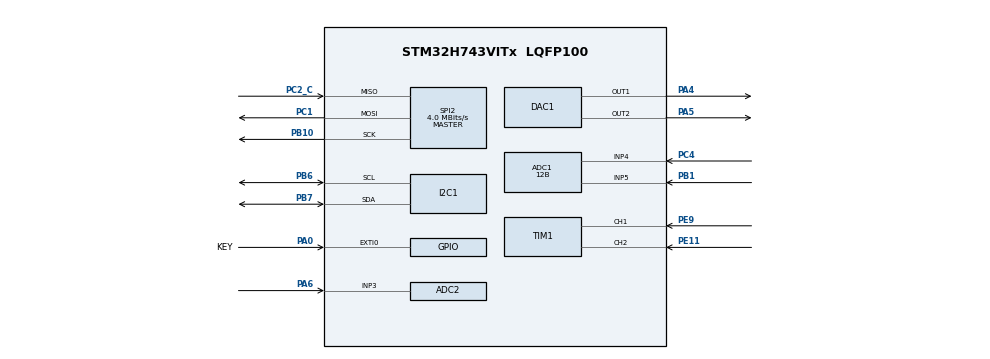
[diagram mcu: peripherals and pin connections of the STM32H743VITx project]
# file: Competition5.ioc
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ADC1.Channel-0\#ChannelRegularConversion=ADC_CHANNEL_5
ADC1.Channel-1\#ChannelRegularConversion=ADC_CHANNEL_4
ADC1.ConversionDataManagement=ADC_CONVERSIONDATA_DMA_CIRCULAR
ADC1.DiscontinuousConvMode=DISABLE
ADC1.ExternalTrigConv=ADC_EXTERNALTRIG_T2_TRGO
ADC1.Mode=ADC_MODE_INDEPENDENT
ADC1.NbrOfConversion=2
ADC1.NbrOfConversionFlag=1
ADC1.OffsetNumber-0\#ChannelRegularConversion=ADC_OFFSET_NONE
ADC1.OffsetNumber-1\#ChannelRegularConversion=ADC_OFFSET_NONE
ADC1.OffsetSignedSaturation-0\#ChannelRegularConversion=DISABLE
ADC1.Rank-0\#ChannelRegularConversion=1
ADC1.Rank-1\#ChannelRegularConversion=2
ADC1.Resolution=ADC_RESOLUTION_12B
ADC1.SamplingTime-0\#ChannelRegularConversion=ADC_SAMPLETIME_16CYCLES_5
ADC1.SamplingTime-1\#ChannelRegularConversion=ADC_SAMPLETIME_16CYCLES_5
ADC1.master=1
ADC2.Channel-3\#ChannelRegularConversion=ADC_CHANNEL_3
ADC2.ConversionDataManagement=ADC_CONVERSIONDATA_DMA_CIRCULAR
ADC2.ExternalTrigConv=ADC_EXTERNALTRIG_T3_TRGO
ADC2.NbrOfConversionFlag=1
ADC2.OffsetNumber-3\#ChannelRegularConversion=ADC_OFFSET_NONE
ADC2.OffsetSignedSaturation-3\#ChannelRegularConversion=DISABLE
ADC2.Rank-3\#ChannelRegularConversion=1
ADC2.Resolution=ADC_RESOLUTION_12B
ADC2.SamplingTime-3\#ChannelRegularConversion=ADC_SAMPLETIME_1CYCLE_5
CORTEX_M7.default_mode_Activation=1
DAC1.DAC_Channel-DAC_OUT1=DAC_CHANNEL_1
DAC1.DAC_Channel-DAC_OUT2=DAC_CHANNEL_2
DAC1.DAC_Trigger-DAC_OUT1=DAC_TRIGGER_T4_TRGO
DAC1.DAC_Trigger-DAC_OUT2=DAC_TRIGGER_T4_TRGO
Dma.ADC1.0.Direction=DMA_PERIPH_TO_MEMORY
Dma.ADC1.0.EventEnable=DISABLE
Dma.ADC1.0.FIFOMode=DMA_FIFOMODE_DISABLE
Dma.ADC1.0.Instance=DMA1_Stream0
Dma.ADC1.0.MemDataAlignment=DMA_MDATAALIGN_HALFWORD
Dma.ADC1.0.MemInc=DMA_MINC_ENABLE
Dma.ADC1.0.Mode=DMA_CIRCULAR
Dma.ADC1.0.PeriphDataAlignment=DMA_PDATAALIGN_HALFWORD
Dma.ADC1.0.PeriphInc=DMA_PINC_DISABLE
Dma.ADC1.0.Polarity=HAL_DMAMUX_REQ_GEN_RISING
Dma.ADC1.0.Priority=DMA_PRIORITY_LOW
Dma.ADC1.0.RequestNumber=1
Dma.ADC1.0.SignalID=NONE
Dma.ADC1.0.SyncEnable=DISABLE
Dma.ADC1.0.SyncPolarity=HAL_DMAMUX_SYNC_NO_EVENT
Dma.ADC1.0.SyncRequestNumber=1
Dma.ADC1.0.SyncSignalID=NONE
Dma.ADC2.2.Direction=DMA_PERIPH_TO_MEMORY
Dma.ADC2.2.EventEnable=DISABLE
Dma.ADC2.2.FIFOMode=DMA_FIFOMODE_DISABLE
Dma.ADC2.2.Instance=DMA1_Stream2
Dma.ADC2.2.MemDataAlignment=DMA_MDATAALIGN_HALFWORD
Dma.ADC2.2.MemInc=DMA_MINC_ENABLE
Dma.ADC2.2.Mode=DMA_CIRCULAR
Dma.ADC2.2.PeriphDataAlignment=DMA_PDATAALIGN_HALFWORD
Dma.ADC2.2.PeriphInc=DMA_PINC_DISABLE
Dma.ADC2.2.Polarity=HAL_DMAMUX_REQ_GEN_RISING
Dma.ADC2.2.Priority=DMA_PRIORITY_LOW
Dma.ADC2.2.RequestNumber=1
Dma.ADC2.2.SignalID=NONE
Dma.ADC2.2.SyncEnable=DISABLE
Dma.ADC2.2.SyncPolarity=HAL_DMAMUX_SYNC_NO_EVENT
Dma.ADC2.2.SyncRequestNumber=1
Dma.ADC2.2.SyncSignalID=NONE
Dma.DAC1_CH1.1.Direction=DMA_MEMORY_TO_PERIPH
Dma.DAC1_CH1.1.EventEnable=DISABLE
Dma.DAC1_CH1.1.FIFOMode=DMA_FIFOMODE_DISABLE
Dma.DAC1_CH1.1.Instance=DMA1_Stream1
Dma.DAC1_CH1.1.MemDataAlignment=DMA_MDATAALIGN_HALFWORD
Dma.DAC1_CH1.1.MemInc=DMA_MINC_ENABLE
Dma.DAC1_CH1.1.Mode=DMA_CIRCULAR
Dma.DAC1_CH1.1.PeriphDataAlignment=DMA_PDATAALIGN_HALFWORD
Dma.DAC1_CH1.1.PeriphInc=DMA_PINC_DISABLE
Dma.DAC1_CH1.1.Polarity=HAL_DMAMUX_REQ_GEN_RISING
Dma.DAC1_CH1.1.Priority=DMA_PRIORITY_VERY_HIGH
Dma.DAC1_CH1.1.RequestNumber=1
Dma.DAC1_CH1.1.SignalID=NONE
Dma.DAC1_CH1.1.SyncEnable=DISABLE
Dma.DAC1_CH1.1.SyncPolarity=HAL_DMAMUX_SYNC_NO_EVENT
Dma.DAC1_CH1.1.SyncRequestNumber=1
Dma.DAC1_CH1.1.SyncSignalID=NONE
Dma.DAC1_CH2.3.Direction=DMA_MEMORY_TO_PERIPH
Dma.DAC1_CH2.3.EventEnable=DISABLE
Dma.DAC1_CH2.3.FIFOMode=DMA_FIFOMODE_DISABLE
Dma.DAC1_CH2.3.Instance=DMA1_Stream3
Dma.DAC1_CH2.3.MemDataAlignment=DMA_MDATAALIGN_HALFWORD
Dma.DAC1_CH2.3.MemInc=DMA_MINC_ENABLE
Dma.DAC1_CH2.3.Mode=DMA_CIRCULAR
Dma.DAC1_CH2.3.PeriphDataAlignment=DMA_PDATAALIGN_HALFWORD
Dma.DAC1_CH2.3.PeriphInc=DMA_PINC_DISABLE
Dma.DAC1_CH2.3.Polarity=HAL_DMAMUX_REQ_GEN_RISING
Dma.DAC1_CH2.3.Priority=DMA_PRIORITY_VERY_HIGH
Dma.DAC1_CH2.3.RequestNumber=1
Dma.DAC1_CH2.3.SignalID=NONE
Dma.DAC1_CH2.3.SyncEnable=DISABLE
Dma.DAC1_CH2.3.SyncPolarity=HAL_DMAMUX_SYNC_NO_EVENT
Dma.DAC1_CH2.3.SyncRequestNumber=1
Dma.DAC1_CH2.3.SyncSignalID=NONE
Dma.Request0=ADC1
Dma.Request1=DAC1_CH1
Dma.Request2=ADC2
Dma.Request3=DAC1_CH2
I2C1.Timing=0x10C0ECFF
Mcu.Family=STM32H7
Mcu.Name=STM32H743VITx
Mcu.Package=LQFP100
NVIC.DMA1_Stream0_IRQn=true\:0\:0\:false\:false\:true\:false\:true\:true
NVIC.DMA1_Stream1_IRQn=true\:0\:0\:false\:false\:true\:false\:true\:true
NVIC.DMA1_Stream2_IRQn=true\:0\:0\:false\:false\:true\:false\:true\:true
NVIC.DMA1_Stream3_IRQn=true\:0\:0\:false\:false\:true\:false\:true\:true
NVIC.EXTI0_IRQn=true\:0\:0\:true\:false\:true\:true\:true\:true
NVIC.PriorityGroup=NVIC_PRIORITYGROUP_4
NVIC.TIM1_BRK_IRQn=true\:0\:0\:false\:false\:true\:true\:true\:true
NVIC.TIM1_CC_IRQn=true\:0\:0\:false\:false\:true\:true\:true\:true
NVIC.TIM1_TRG_COM_IRQn=true\:0\:0\:false\:false\:true\:true\:true\:true
NVIC.TIM1_UP_IRQn=true\:0\:0\:false\:false\:true\:true\:true\:true
PA0.GPIO_Label=KEY
PA0.GPIO_ModeDefaultEXTI=GPIO_MODE_IT_FALLING
PA0.GPIO_PuPd=GPIO_PULLUP
PA0.Signal=GPXTI0
PA4.Signal=SharedAnalog_PA4
PA5.Signal=SharedAnalog_PA5
PA6.Signal=SharedAnalog_PA6
PB1.Signal=SharedAnalog_PB1
PB10.Mode=Full_Duplex_Master
PB10.Signal=SPI2_SCK
PB6.Mode=I2C
PB6.Signal=I2C1_SCL
PB7.Mode=I2C
PB7.Signal=I2C1_SDA
PC1.Mode=Full_Duplex_Master
PC1.Signal=SPI2_MOSI
PC2_C.Mode=Full_Duplex_Master
PC2_C.Signal=SPI2_MISO
PC4.Signal=SharedAnalog_PC4
PE11.Signal=S_TIM1_CH2
PE9.Signal=S_TIM1_CH1
PH0-OSC_IN\ (PH0).Mode=HSE-External-Oscillator
PH0-OSC_IN\ (PH0).Signal=RCC_OSC_IN
PH1-OSC_OUT\ (PH1).Mode=HSE-External-Oscillator
PH1-OSC_OUT\ (PH1).Signal=RCC_OSC_OUT
ProjectManager.HeapSize=0x200
ProjectManager.StackSize=0x400
ProjectManager.TargetToolchain=STM32CubeIDE
RCC.ADCFreq_Value=33333333.333333332
RCC.APB1Freq_Value=100000000
RCC.APB2Freq_Value=100000000
RCC.APB3Freq_Value=100000000
RCC.APB4Freq_Value=100000000
RCC.CortexFreq_Value=400000000
RCC.D1PPRE=RCC_APB3_DIV2
RCC.D2PPRE1=RCC_APB1_DIV2
RCC.D2PPRE2=RCC_APB2_DIV2
RCC.D3PPRE=RCC_APB4_DIV2
RCC.DIVM1=5
RCC.DIVM2=25
RCC.DIVM3=5
RCC.DIVN1=160
RCC.DIVN2=400
RCC.DIVN3=32
RCC.DIVP2=12
RCC.DIVP3=5
RCC.HCLKFreq_Value=200000000
RCC.HPRE=RCC_HCLK_DIV2
RCC.PLLSourceVirtual=RCC_PLLSOURCE_HSE
RCC.SPI123CLockSelection=RCC_SPI123CLKSOURCE_PLL3
RCC.SYSCLKFreq_VALUE=400000000
RCC.SYSCLKSource=RCC_SYSCLKSOURCE_PLLCLK
RCC.USBFreq_Value=400000000
SH.S_TIM1_CH1.0=TIM1_CH1,Encoder_Interface
SH.S_TIM1_CH2.0=TIM1_CH2,Encoder_Interface
SH.SharedAnalog_PA4.0=GPIO_Analog
SH.SharedAnalog_PA4.1=DAC1_OUT1,DAC_OUT1
SH.SharedAnalog_PA5.0=GPIO_Analog
SH.SharedAnalog_PA5.1=DAC1_OUT2,DAC_OUT2
SH.SharedAnalog_PA6.0=GPIO_Analog
SH.SharedAnalog_PA6.1=ADC1_INP3
SH.SharedAnalog_PA6.2=ADC2_INP3,IN3-Single-Ended
SH.SharedAnalog_PB1.0=GPIO_Analog
SH.SharedAnalog_PB1.1=ADC2_INP5
SH.SharedAnalog_PB1.2=ADC1_INP5,IN5-Single-Ended
SH.SharedAnalog_PC4.0=GPIO_Analog
SH.SharedAnalog_PC4.1=ADC1_INP4,IN4-Single-Ended
SPI2.BaudRatePrescaler=SPI_BAUDRATEPRESCALER_8
SPI2.CLKPolarity=SPI_POLARITY_HIGH
SPI2.CalculateBaudRate=4.0 MBits/s
SPI2.DataSize=SPI_DATASIZE_8BIT
SPI2.Direction=SPI_DIRECTION_2LINES
SPI2.Mode=SPI_MODE_MASTER
SPI2.VirtualType=VM_MASTER
TIM1.EncoderMode=TIM_ENCODERMODE_TI12
TIM2.AutoReloadPreload=TIM_AUTORELOAD_PRELOAD_ENABLE
TIM2.Period=200-1
TIM2.TIM_MasterOutputTrigger=TIM_TRGO_UPDATE
TIM3.AutoReloadPreload=TIM_AUTORELOAD_PRELOAD_ENABLE
TIM3.Period=200-1
TIM3.TIM_MasterOutputTrigger=TIM_TRGO_UPDATE
TIM4.AutoReloadPreload=TIM_AUTORELOAD_PRELOAD_ENABLE
TIM4.Period=20000-1
TIM4.TIM_MasterOutputTrigger=TIM_TRGO_UPDATE
TIM5.AutoReloadPreload=TIM_AUTORELOAD_PRELOAD_ENABLE
TIM5.Period=20000-1
TIM5.TIM_MasterOutputTrigger=TIM_TRGO_UPDATE
VP_MEMORYMAP_VS_MEMORYMAP.Mode=CurAppReg
VP_TIM2_VS_ClockSourceINT.Mode=Internal
VP_TIM3_VS_ClockSourceINT.Mode=Internal
VP_TIM4_VS_ClockSourceINT.Mode=Internal
VP_TIM5_VS_ClockSourceINT.Mode=Internal
board=custom

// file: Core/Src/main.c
/* USER CODE BEGIN Header */
/**
  ******************************************************************************
  * @file           : main.c
  * @brief          : Main program body
  ******************************************************************************
  * @attention
  *
  * Copyright (c) 2026 STMicroelectronics.
  * All rights reserved.
  *
  * This software is licensed under terms that can be found in the LICENSE file
  * in the root directory of this software component.
  * If no LICENSE file comes with this software, it is provided AS-IS.
  *
  ******************************************************************************
  */
/* USER CODE END Header */
#include "main.h"
#include "adc.h"
#include "dac.h"
#include "dma.h"
#include "i2c.h"
#include "spi.h"
#include "tim.h"
#include "gpio.h"

/* USER CODE BEGIN Includes */
#include "mainoop.h"
/* USER CODE END Includes */

void SystemClock_Config(void);
void PeriphCommonClock_Config(void);
static void MPU_Config(void);

int main(void)
{

  /* MPU Configuration--------------------------------------------------------*/
  MPU_Config();

  /* MCU Configuration--------------------------------------------------------*/

  /* Reset of all peripherals, Initializes the Flash interface and the Systick. */
  HAL_Init();

  /* Configure the system clock */
  SystemClock_Config();

  /* Configure the peripherals common clocks */
  PeriphCommonClock_Config();

  /* Initialize all configured peripherals */
  MX_GPIO_Init();
  MX_DMA_Init();
  MX_ADC1_Init();
  MX_DAC1_Init();
  MX_I2C1_Init();
  MX_TIM2_Init();
  MX_TIM4_Init();
  MX_ADC2_Init();
  MX_TIM1_Init();
  MX_TIM3_Init();
  MX_TIM5_Init();
  MX_SPI2_Init();
  /* USER CODE BEGIN 2 */
  main_init();
  /* USER CODE END 2 */

  /* Infinite loop */
  /* USER CODE BEGIN WHILE */
  while (1)
  {
	  main_loop();
    /* USER CODE END WHILE */

  }
}

void SystemClock_Config(void)
{
  RCC_OscInitTypeDef RCC_OscInitStruct = {0};
  RCC_ClkInitTypeDef RCC_ClkInitStruct = {0};

  /** Supply configuration update enable
  */
  HAL_PWREx_ConfigSupply(PWR_LDO_SUPPLY);

  /** Configure the main internal regulator output voltage
  */
  __HAL_PWR_VOLTAGESCALING_CONFIG(PWR_REGULATOR_VOLTAGE_SCALE1);

  while(!__HAL_PWR_GET_FLAG(PWR_FLAG_VOSRDY)) {}

  /** Initializes the RCC Oscillators according to the specified parameters
  * in the RCC_OscInitTypeDef structure.
  */
  RCC_OscInitStruct.OscillatorType = RCC_OSCILLATORTYPE_HSE;
  RCC_OscInitStruct.HSEState = RCC_HSE_ON;
  RCC_OscInitStruct.PLL.PLLState = RCC_PLL_ON;
  RCC_OscInitStruct.PLL.PLLSource = RCC_PLLSOURCE_HSE;
  RCC_OscInitStruct.PLL.PLLM = 5;
  RCC_OscInitStruct.PLL.PLLN = 160;
  RCC_OscInitStruct.PLL.PLLP = 2;
  RCC_OscInitStruct.PLL.PLLQ = 2;
  RCC_OscInitStruct.PLL.PLLR = 2;
  RCC_OscInitStruct.PLL.PLLRGE = RCC_PLL1VCIRANGE_2;
  RCC_OscInitStruct.PLL.PLLVCOSEL = RCC_PLL1VCOWIDE;
  RCC_OscInitStruct.PLL.PLLFRACN = 0;
  if (HAL_RCC_OscConfig(&RCC_OscInitStruct) != HAL_OK)
  {
    Error_Handler();
  }

  /** Initializes the CPU, AHB and APB buses clocks
  */
  RCC_ClkInitStruct.ClockType = RCC_CLOCKTYPE_HCLK|RCC_CLOCKTYPE_SYSCLK
                              |RCC_CLOCKTYPE_PCLK1|RCC_CLOCKTYPE_PCLK2
                              |RCC_CLOCKTYPE_D3PCLK1|RCC_CLOCKTYPE_D1PCLK1;
  RCC_ClkInitStruct.SYSCLKSource = RCC_SYSCLKSOURCE_PLLCLK;
  RCC_ClkInitStruct.SYSCLKDivider = RCC_SYSCLK_DIV1;
  RCC_ClkInitStruct.AHBCLKDivider = RCC_HCLK_DIV2;
  RCC_ClkInitStruct.APB3CLKDivider = RCC_APB3_DIV2;
  RCC_ClkInitStruct.APB1CLKDivider = RCC_APB1_DIV2;
  RCC_ClkInitStruct.APB2CLKDivider = RCC_APB2_DIV2;
  RCC_ClkInitStruct.APB4CLKDivider = RCC_APB4_DIV2;

  if (HAL_RCC_ClockConfig(&RCC_ClkInitStruct, FLASH_LATENCY_2) != HAL_OK)
  {
    Error_Handler();
  }
}

void PeriphCommonClock_Config(void)
{
  RCC_PeriphCLKInitTypeDef PeriphClkInitStruct = {0};

  /** Initializes the peripherals clock
  */
  PeriphClkInitStruct.PeriphClockSelection = RCC_PERIPHCLK_ADC;
  PeriphClkInitStruct.PLL2.PLL2M = 25;
  PeriphClkInitStruct.PLL2.PLL2N = 400;
  PeriphClkInitStruct.PLL2.PLL2P = 12;
  PeriphClkInitStruct.PLL2.PLL2Q = 2;
  PeriphClkInitStruct.PLL2.PLL2R = 2;
  PeriphClkInitStruct.PLL2.PLL2RGE = RCC_PLL2VCIRANGE_0;
  PeriphClkInitStruct.PLL2.PLL2VCOSEL = RCC_PLL2VCOWIDE;
  PeriphClkInitStruct.PLL2.PLL2FRACN = 0;
  PeriphClkInitStruct.AdcClockSelection = RCC_ADCCLKSOURCE_PLL2;
  if (HAL_RCCEx_PeriphCLKConfig(&PeriphClkInitStruct) != HAL_OK)
  {
    Error_Handler();
  }
}

 /* MPU Configuration */

void MPU_Config(void)
{
  MPU_Region_InitTypeDef MPU_InitStruct = {0};

  /* Disables the MPU */
  HAL_MPU_Disable();

  /** Initializes and configures the Region and the memory to be protected
  */
  MPU_InitStruct.Enable = MPU_REGION_ENABLE;
  MPU_InitStruct.Number = MPU_REGION_NUMBER0;
  MPU_InitStruct.BaseAddress = 0x0;
  MPU_InitStruct.Size = MPU_REGION_SIZE_4GB;
  MPU_InitStruct.SubRegionDisable = 0x87;
  MPU_InitStruct.TypeExtField = MPU_TEX_LEVEL0;
  MPU_InitStruct.AccessPermission = MPU_REGION_NO_ACCESS;
  MPU_InitStruct.DisableExec = MPU_INSTRUCTION_ACCESS_DISABLE;
  MPU_InitStruct.IsShareable = MPU_ACCESS_SHAREABLE;
  MPU_InitStruct.IsCacheable = MPU_ACCESS_NOT_CACHEABLE;
  MPU_InitStruct.IsBufferable = MPU_ACCESS_NOT_BUFFERABLE;

  HAL_MPU_ConfigRegion(&MPU_InitStruct);
  /* Enables the MPU */
  HAL_MPU_Enable(MPU_PRIVILEGED_DEFAULT);

}

void Error_Handler(void)
{
  __disable_irq();
  while (1)
  {
  }
}
